# ET6801 register map
Vendor: ETMCU Inc.; File version: v0.0.1
CPU: CM7 r2p1, little endian, MPU, FPU, I-cache, D-cache, ITCM, DTCM, 4 interrupt priority bits
Registers are 32-bit, read-write, reset 0x0 unless marked. A register's access mark holds for its fields unless they carry their own. Offsets are from the block's base; [hi:lo] are bit positions.

## UART0 — Provide an overview of the purpose and functionality of the peripheral: UART
Base 0x40500000
Same registers: UART1 0x40501000, UART2 0x40502000, UART3 0x40503000, UART4 0x40504000, UART5 0x40505000, UART6 0x40506000, UART7 0x40507000
0x00 RBR read — Receive Buffer Register.
  [15:0] RBR — This register contains the data byte received on the serial input port (sin) in UART mode or the serial infrared input(sir_in) in infrared mode. The data in this register is valid only if the Data Ready (DR) bit in the Line status Register(LSR) is set.
0x00 THR write — Transmit Holding Register.This register can be accessed only when the DLAB bit (LCR) is cleared.
  [15:0] THR — This register contains data to be transmitted on the serial output port (sout) in UART mode or the serial infrared output(sir_out_n) in infrared mode.
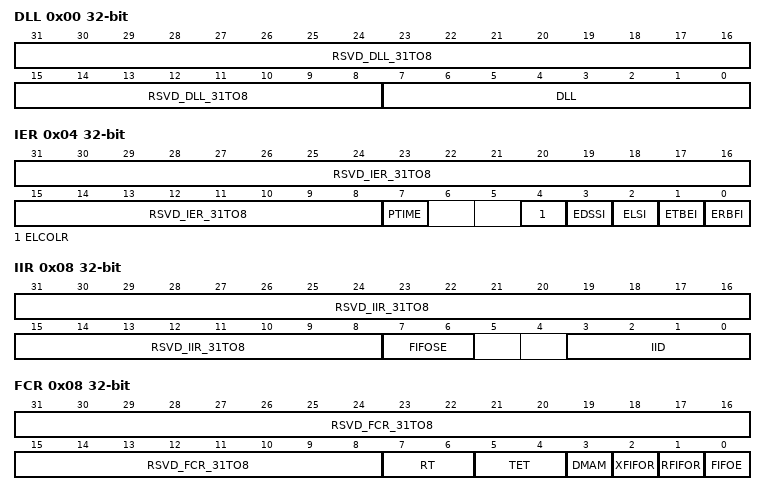
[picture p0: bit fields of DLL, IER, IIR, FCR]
0x00 DLL — Divisor Latch (Low).This register can be accessed only when the DLAB bit (LCR) is set and the UART is not busy.
  [31:8] RSVD_DLL_31TO8 read — DLL 31to8 Reserved bits and read as zero (0)
  [7:0] DLL — This register makes up the lower 8-bits of a 16-bit, read/write, Divisor Latch register that contains the baud rate divisor for the UART.
0x04 IER — Interrupt Enable Register.This register can be accessed only when the DLAB bit (LCR) is cleared.
  [31:8] RSVD_IER_31TO8 read — IER 31to8 Reserved bits and read as zero (0).
  [7] PTIME — This is used to enable/disable the generation of THRE Interrupt
  [4] ELCOLR — Interrupt Enable Register: ELCOLR, this bit controls the method for clearing the status in the LSR register. This is applicable only for Overrun Error, Parity Error, Framing Error, and Break Interrupt status bits
  [3] EDSSI — This is used to enable/disable the generation of Receiver Line Status Interrupt.This is the highest priority interrupt.
  [2] ELSI — This is used to enable/disable the generation of Transmitter Holding Register Empty Interrupt. This is the third highest priority interrupt.
  [1] ETBEI — This is used to enable/disable the generation of Received Data Available Interrupt and the Character Timeout Interrupt (if in FIFO mode and FIFO's enabled). These are the second highest priority interrupts.
  [0] ERBFI — This is used to enable/disable the generation of Received Data Available Interrupt and the Character Timeout Interrupt (if in FIFO mode and FIFO's enabled). These are the second highest priority interrupts
0x04 DLH (alternate view of IER) — Divisor Latch High (DLH) Register.This register can be accessed only when the DLAB bit(LCR) is set and the UART is not busy.
  [7:0] DLH — Upper 8-bits of a 16-bit, read/write, Divisor Latch register that contains the baud rate divisor for the UART.
0x08 IIR read — Interrupt Identification Register
  [31:8] RSVD_IIR_31TO8 — IIR 31to8 Reserved bits and read as 0.
  [7:6] FIFOSE — This is used to indicate whether the FIFOs are enabled or disabled.
  [3:0] IID — This indicates the highest priority pending interrupt which can be one of the following types specified in Values.
0x08 FCR (alternate view of IIR) — FIFO Control Register
  [31:8] RSVD_FCR_31TO8 read — FCR 31to8 Reserved bits and read as 0
  [7:6] RT write — This is used to select the trigger level in the receiver FIFO at which the Received Data Available Interrupt will be generated. In auto flow control mode, it is used to determine when the rts_n signal will be de-asserted only when RTC_FCT is disabled.
  [5:4] TET write — This is used to select the empty threshold level at which the THRE Interrupts will be generated when the mode is active.
  [3] DMAM write — This is used to select DMA mode
  [2] XFIFOR write — This resets the control portion of the transmit FIFO and treats the FIFO as empty. This will also de-assert the DMA TX request and single signals when additional DMA handshaking signals are selected.
  [1] RFIFOR write — This resets the controlportion of the receive FIFO and treats the FIFO as empty. This will also de-assert the DMA RX request and single signals when additional DMA handshaking signals are selected.
  [0] FIFOE write — This enables/disables the transmit(XMIT) and receive (RCVR) FIFOs.
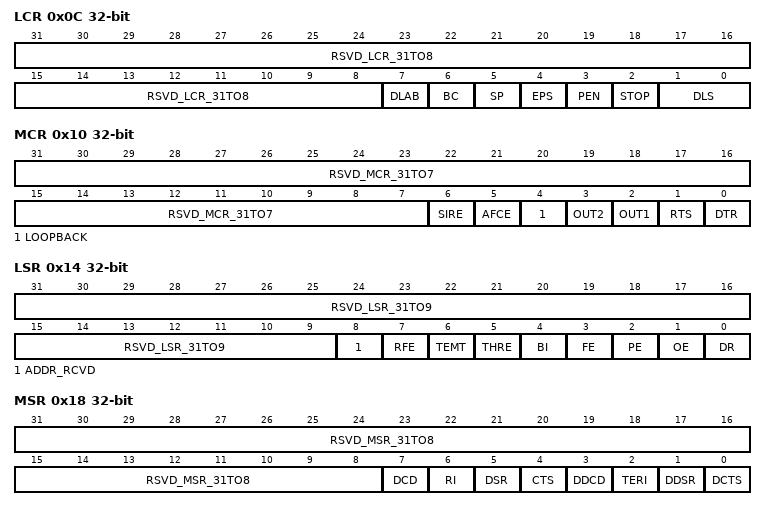
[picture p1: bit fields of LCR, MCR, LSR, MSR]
0x0C LCR — Line Control Register
  [31:8] RSVD_LCR_31TO8 read — LCR 31to8 Reserved bits and read as 0.
  [7] DLAB — Divisor Latch Access Bit.This bit is used to enable reading and writing of the Divisor Latch register (DLL and DLH/LPDLL and LPDLH) to set the baud rate of the UART.
  [6] BC — This is used to cause a break condition to be transmitted to the receiving device.
  [5] SP — writeable only when UART is not busy (USR[0] is 0);
  [4] EPS — writeable only when UART is not busy (USR[0] is zero), otherwise always writable and always readable.
  [3] PEN — writeable only when UART is not busy (USR[0] is zero), otherwise always writable and always readable.
  [2] STOP — writeable only when UART is not busy (USR[0] is zero), otherwise always writable and always readable.
  [1:0] DLS — writeable only when UART is not busy (USR[0] is zero), otherwise always writable and always readable.
0x10 MCR
  [31:7] RSVD_MCR_31TO7 read — MCR 31to7 Reserved bits read as 0.
  [6] SIRE — This is used to enable/ disable the IrDA SIR Mode features as described in section 'IrDA 1.0 SIR Protocol' in the databook.
  [5] AFCE — When FIFOs are enabled and the Auto Flow Control Enable (AFCE) bit is set, Auto Flow Control features are enabled as described in section 'Auto Flow Control' in data book.
  [4] LOOPBACK — LoopBack Bit
  [3] OUT2 — This is used to directly control the user-designated Output2 (out2_n) output.
  [2] OUT1 — This is used to directly control the Request to Send (rts_n) output. The Request To Send (rts_n) output is used to inform the modem or data set that the UART is ready to exchange data.
  [1] RTS — This is used to directly control the Request to Send (rts_n) output. The Request To Send (rts_n) output is used to inform the modem or data set that the UART is ready to exchange data.
  [0] DTR — This is used to directly control the Data Terminal Ready (dtr_n) output. The value written to this location is inverted and driven out on dtr_n.
0x14 LSR read — Line Status Register
  [31:9] RSVD_LSR_31TO9 — LSR 31to9 Reserved bits read as zero.
  [8] ADDR_RCVD — This bit is used to indicate the 9th bit of the receive data is set to 1. This bit can also be used to indicate whether the incoming character is address or data.
  [7] RFE — This is used to indicate if there is at least one parity error, framing error, or break indication in the FIFO.
  [6] TEMT — This bit is set whenever the Transmitter Shift Register and the FIFO are both empty. If in the non-FIFO mode or FIFO's are disabled, this bit is set whenever the Transmitter Holding Register and the Transmitter Shift Register are both empty.
  [5] THRE — This bit indicates that the THR or TX FIFO is empty.
  [4] BI — This is used to indicate the detection of a break sequence on the serial input data.
  [3] FE — This is used to indicate the occurrence of a framing error in the receiver. A framing error occurs when the receiver does not detect a valid STOP bit in the received data.
  [2] PE — This is used to indicate the occurrence of a parity error in the receiver if the Parity Enable (PEN) bit (LCR[3]) is set. In the FIFO mode, since the parity error is associated with a character received, it is revealed when the character with the parity error arrives at the top of the FIFO.
  [1] OE — This is used to indicate the occurrence of an overrun error. This occurs if a new data character was received before the previous data was read.
  [0] DR — This is used to indicate that the receiver contains at least one character in the RBR or the receiver FIFO. This bit is cleared when the RBR is read in the non-FIFO mode, or when the receiver FIFO is empty, in the FIFO mode.
0x18 MSR read — Modem Status Register
  [31:8] RSVD_MSR_31TO8 — MSR 31to8 Reserved bits read as 0.
  [7] DCD — This is used to indicate the current state of the modem control line dcd_n. That is this bit is the complement dcd_n. When the Data Carrier Detect input (dcd_n) is asserted it is an indication that the carrier has been detected by the modem or data set.
  [6] RI — This is used to indicate the current state of the modem control line ri_n. That is this bit is the complement ri_n. When the Ring Indicator input (ri_n) is asserted it is an indication that a telephone ringing signal has been received by the modem or data set.
  [5] DSR — This is used to indicate the current state of the modem control line dsr_n. That is this bit is the complement dsr_n. When the Data Set Ready input (dsr_n) is asserted it is an indication that the modem or data set is ready to establish communications with the DW_apb_uart.
  [4] CTS — This is used to indicate the current state of the modem control line cts_n.
  [3] DDCD — This is used to indicate that the modem control line dcd_n has changed since the last time the MSR was read.
  [2] TERI — This is used to indicate that a change on the input ri_n (from an active low, to an inactive high state) has occurred since the last time the MSR was read.
  [1] DDSR — This is used to indicate that the modem control line dsr_n has changed since the last time the MSR was read.
  [0] DCTS — This is used to indicate that the modem control line cts_n has changed since the last time the MSR was read.
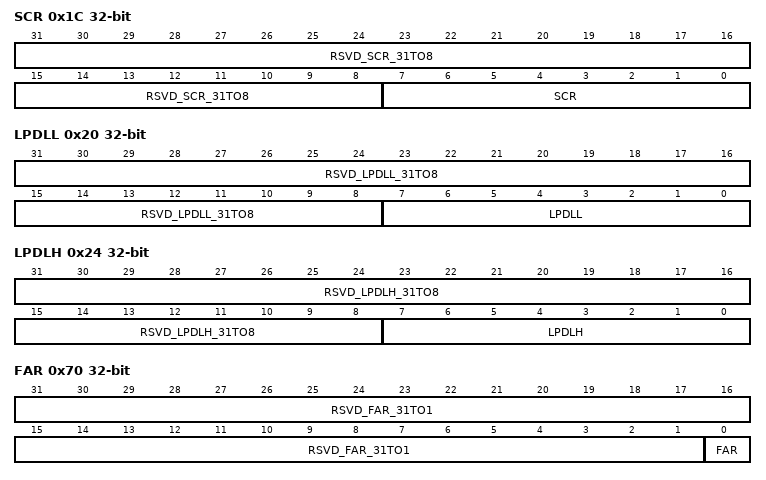
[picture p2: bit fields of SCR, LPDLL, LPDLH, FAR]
0x1C SCR — Scratchpad Register
  [31:8] RSVD_SCR_31TO8 read — SCR 31to8 Reserved bits read as 0.
  [7:0] SCR — This register is for programmers to use as a temporary storage space. It has no defined purpose in the Uart.
0x20 LPDLL — Low Power Divisor Latch Low
  [31:8] RSVD_LPDLL_31TO8 read — LPDLL 31to8 Reserved bits read as 0.
  [7:0] LPDLL — This register makes up the lower 8-bits of a 16-bit, read/write, Low Power Divisor Latch register that contains the baud rate divisor for the UART which must give a baud rate of 115.2K. This is required for SIR Low Power (minimum pulse width) detection at the receiver.
0x24 LPDLH — Low Power Divisor Latch High
  [31:8] RSVD_LPDLH_31TO8 read — LPDLH 31to8 Reserved and read as 0.
  [7:0] LPDLH — This register makes up the upper 8-bits of a 16-bit, read/write, Low Power Divisor Latch register that contains the baud rate divisor for the UART which must give a baud rate of 115.2K.
0x30 SRBR read — Shadow Receive Buffer Register
  [15:0] SRBRN — Shadow Receive Buffer Register n. This is a shadow register for the RBR and has been allocated sixteen 32-bit locations so as to accommodate burst accesses from the master. This register contains the data byte received on the serial input port (sin) in UART mode or the serial infrared input (sir_in) in infrared mode. The data in this register is valid only if the Data Ready (DR) bit in the Line status Register (LSR) is set.
0x30 STHR write — Shadow Transmit Holding Register.
  [15:0] STHRN — Shadow Transmit Holding Register n. This is a shadow register for the THR and has been allocated sixteen 32-bit locations so as to accommodate burst accesses from the master. This register contains data to be transmitted on the serial output port (sout) in UART mode or the serial infrared output (sir_out_n) in infrared mode. Data should only be written to the THR when the THR Empty (THRE) bit (LSR[5])is set.
0x70 FAR — FIFO Access Register.
  [31:1] RSVD_FAR_31TO1 read — FAR 31to1 Reserved bits read as 0.
  [0] FAR — Writes will have no effect when FIFO_ACCESS == No, always readable. This register is use to enable a FIFO access mode for testing, so that the receive FIFO can be written by the master and the transmit FIFO can be read by the master when FIFO's are implemented and enabled. When FIFOs are not implemented or not enabled it allows the RBR to be written by the master and the THR to be read by the master.
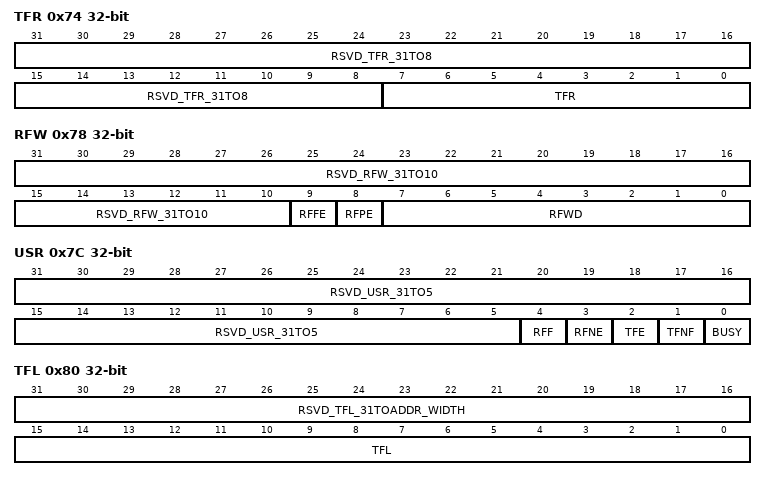
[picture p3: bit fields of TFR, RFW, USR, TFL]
0x74 TFR
  [31:8] RSVD_TFR_31TO8 read — TFR 31to8 Reserved bits read as 0.
  [7:0] TFR read — These bits are only valid when FIFO access mode is enabled(FAR[0] is set to one). When FIFO's are implemented and enabled, reading this register gives the data at the top of the transmit FIFO. Each consecutive read pops the transmit FIFO and gives the next data value that is currently at the top of the FIFO. When FIFO's are not implemented or not enabled, reading this register gives the data in the THR.
0x78 RFW — Receive FIFO Write
  [31:10] RSVD_RFW_31TO10 read — RFW 31to10 Reserved bits read as 0.
  [9] RFFE write — These bits are only valid when FIFO access mode is enabled(FAR[0] is set to one). When FIFO's are implemented and enabled, this bit is used to write framing error detection information to the receive FIFO. When FIFO's are not implemented or not enabled, this bit is used to write framing error detection information to the RBR.
  [8] RFPE write — These bits are only valid when FIFO access mode is enabled(FAR[0] is set to one). When FIFO's are implemented and enabled, this bit is used to write parity error detection information to the receive FIFO. When FIFO's are not implemented or not enabled, this bit is used to write parity error detection information to the RBR.
  [7:0] RFWD write — These bits are only valid when FIFO access mode is enabled (FAR[0] is set to one). When FIFO's are implemented and enabled, the data that is written to the RFWD is pushed into the receive FIFO. Each consecutive write pushes the new data to the next write location in the receive FIFO. When FIFO's are not implemented or not enabled, the data that is written to the RFWD is pushed into the RBR.
0x7C USR — UART Status register
  [31:5] RSVD_USR_31TO5 read — USR 31to5 Reserved bits read as 0.
  [4] RFF read — This bit is only valid when FIFO_STAT == YES. This is used to indicate that the receive FIFO is completely full. That is: This bit is cleared when the RX FIFO is no longer full.
  [3] RFNE read — This bit is only valid when FIFO_STAT == YES. This is used to indicate that the receive FIFO contains one or more entries. This bit is cleared when the RX FIFO is empty.
  [2] TFE read — This bit is only valid when FIFO_STAT == YES. This is used to indicate that the transmit FIFO is completely empty. This bit is cleared when the TX FIFO is no longer empty.
  [1] TFNF read — This bit is only valid when FIFO_STAT == YES. This is used to indicate that the transmit FIFO is not full. This bit is cleared when the TX FIFO is full.
  [0] BUSY read — This indicates that a serial transfer is in progress, when cleared indicates that the DW_apb_uart is idle or inactive.
0x80 TFL — Transmit FIFO Level.
  [31:16] RSVD_TFL_31TOADDR_WIDTH read — TFL 31 to ADDR_WIDTH Reserved bits read as 0.
  [15:0] TFL read — This indicates the number of data entries in the transmit FIFO.
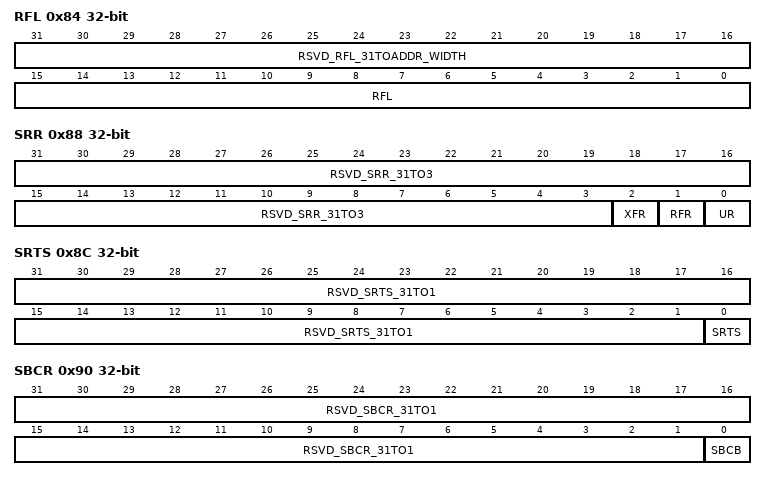
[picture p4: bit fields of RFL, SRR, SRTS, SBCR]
0x84 RFL — This indicates the number of data entries in the transmit FIFO.
  [31:16] RSVD_RFL_31TOADDR_WIDTH read — RFL 31 to ADDR_WIDTH Reserved bits read as 0.
  [15:0] RFL read — This indicates the number of data entries in the receive FIFO.
0x88 SRR — Software Reset Register.
  [31:3] RSVD_SRR_31TO3 read — SRR 31to3 Reserved bits read as 0.
  [2] XFR write — Thisis a shadow register for the XMIT FIFO Reset bit (FCR[2]). This can be used to remove the burden on software having to store previously written FCR values (which are pretty static) just to reset the transmit FIFO. This resets the control portion of the transmit FIFO and treats the FIFO as empty.
  [1] RFR write — This is a shadow register for the RCVR FIFO Reset bit (FCR[1]). This can be used to remove the burden on software having to store previously written FCR values (which are pretty static) just to reset the reeive FIFO. This resets the control portion of the receive FIFO and treats the FIFO as empty.
  [0] UR write — This asynchronously resets the DW_apb_uart and synchronously removes the reset assertion. For a two clock implementation both pclk and sclk domains will be reset.
0x8C SRTS — Shadow Request to Send.
  [31:1] RSVD_SRTS_31TO1 read — SRTS 31to1 Reserved bits read as 0.
  [0] SRTS — This is a shadow register for the RTS bit (MCR[1]), this can be used to remove the burden of having to performing a read modify write on the MCR.
0x90 SBCR — Shadow Break Control Register.
  [31:1] RSVD_SBCR_31TO1 read — SBCR 31to1 Reserved bits read as 0.
  [0] SBCB — This is a shadow register for the Break bit (LCR[6]), this can be used to remove the burden of having to performing a read modify write on the LCR.
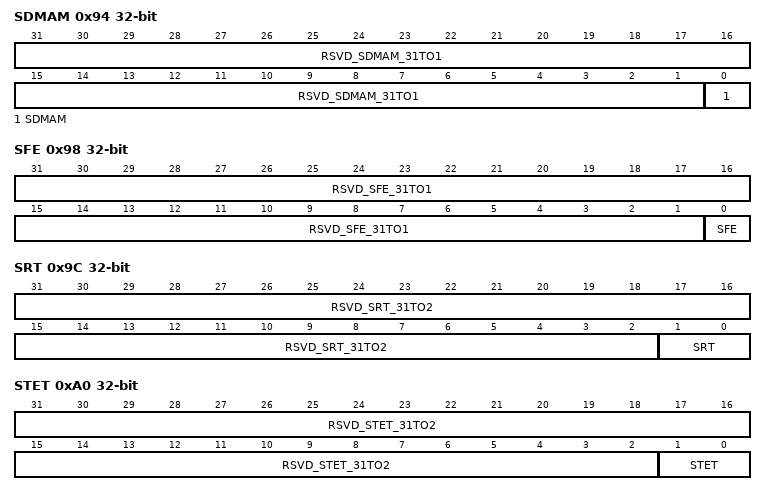
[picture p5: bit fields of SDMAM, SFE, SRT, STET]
0x94 SDMAM — Shadow DMA Mode Register.
  [31:1] RSVD_SDMAM_31TO1 read — SDMAM 31to1 Reserved bits read as 0.
  [0] SDMAM — This is a shadow register for the DMA mode bit (FCR[3]). This can be used to remove the burden of having to store the previously written value to the FCR in memory and having to mask this value so that only the DMA Mode bit gets updated. This determines the DMA signalling mode used for the dma_tx_req_n and dma_rx_req_n output signals when additional DMA handshaking signals are not selected (DMA_EXTRA == NO).
0x98 SFE — Shadow FIFO Enable Register.
  [31:1] RSVD_SFE_31TO1 read — SFE 31to1 Reserved bits read as 0.
  [0] SFE — This is a shadow register for the FIFO enable bit (FCR[0]). This can be used to remove the burden of having to store the previously written value to the FCR in memory and having to mask this value so that only the FIFO enable bit gets updated. This enables/disables the transmit (XMIT) and receive (RCVR) FIFO's. If this bit is set to zero (disabled) after being enabled then both the XMIT and RCVR controller portion of FIFO's will be reset.
0x9C SRT — Shadow RCVR Trigger Register.
  [31:2] RSVD_SRT_31TO2 read — SRT 31to2 Reserved bits read as 0.
  [1:0] SRT — This is a shadow register for the RCVR trigger bits(FCR[7:6]). This can be used to remove the burden of having to store the previously written value to the FCR in memory and having to mask this value so that only the RCVR trigger bit gets updated.
0xA0 STET — Shadow TX Empty Trigger Register.
  [31:2] RSVD_STET_31TO2 read — STET 31to2 Reserved bits read as 0.
  [1:0] STET — This is a shadow register for the TX empty trigger bits (FCR[5:4]). This can be used to remove the burden of having to store the previously written value to the FCR in memory and having to mask this value so that only the TX empty trigger bit gets updated.
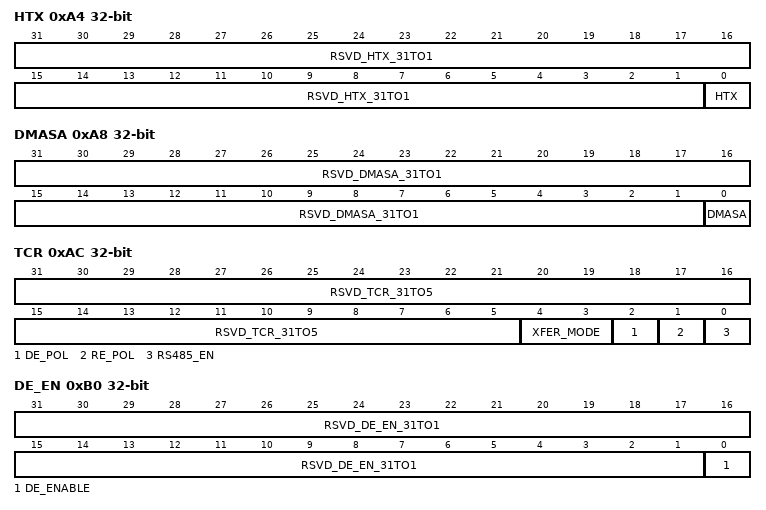
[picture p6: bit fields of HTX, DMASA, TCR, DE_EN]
0xA4 HTX — Halt TX
  [31:1] RSVD_HTX_31TO1 read — HTX 31to1 Reserved bits read as 0.
  [0] HTX * Varies — This register is use to halt transmissions for testing, so that the transmit FIFO can be filled by the master when FIFO's are implemented and enabled.
0xA8 DMASA — DMA Software Acknowledge Register.
  [31:1] RSVD_DMASA_31TO1 read — DMASA 31to1 Reserved bits read as 0.
  [0] DMASA write — This register is use to perform DMA software acknowledge if a transfer needs to be terminated due to an error condition. For example, if the DMA disables the channel, then the uart should clear its request.
0xAC TCR — Transceiver Control Register.
  [31:5] RSVD_TCR_31TO5 read — TCR 31to5 Reserved bits read as 0.
  [4:3] XFER_MODE — Transfer Mode.
  [2] DE_POL — Driver Enable Polarity.
  [1] RE_POL — Receiver Enable Polarity.
  [0] RS485_EN — RS485 Transfer Enable.
0xB0 DE_EN — Driver Output Enable Register.
  [31:1] RSVD_DE_EN_31TO1 read — DE_EN 31to1 Reserved bits read as 0.
  [0] DE_ENABLE — The 'DE Enable' register bit is used to control assertion and de-assertion of 'de' signal.
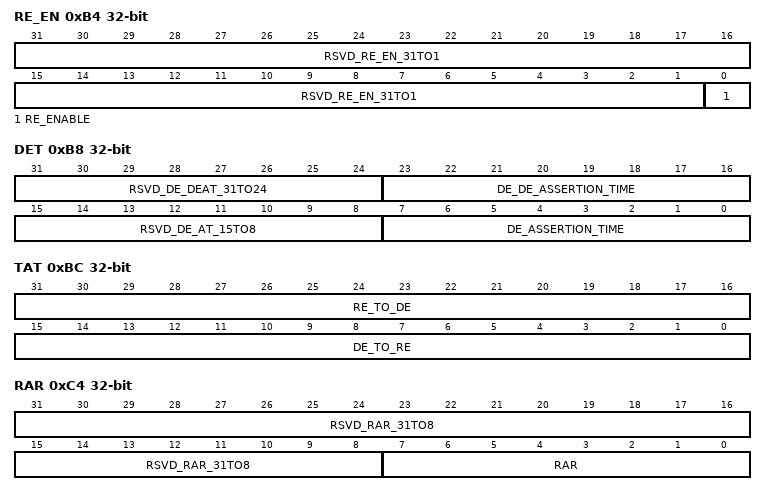
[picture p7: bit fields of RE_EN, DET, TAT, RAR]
0xB4 RE_EN — Receiver Output Enable Register.
  [31:1] RSVD_RE_EN_31TO1 read — RE_EN 31to1 Reserved bits read as 0.
  [0] RE_ENABLE — The 'RE Enable' register bit is used to control assertion and de-assertion of 're' signal.
0xB8 DET — Driver Output Enable Timing Register.
  [31:24] RSVD_DE_DEAT_31TO24 read — DET 31to24 Reserved bits read as 0.
  [23:16] DE_DE_ASSERTION_TIME — Driver Enable de-assertion time.
  [15:8] RSVD_DE_AT_15TO8 read — DET 15to8 Reserved bits read as 0.
  [7:0] DE_ASSERTION_TIME — Driver Enable assertion time.
0xBC TAT — TurnAround Timing Register.
  [31:16] RE_TO_DE — Receiver Enable to Driver Enable TurnAround time.
  [15:0] DE_TO_RE — Driver Enable to Receiver Enable TurnAround time.
0xC0 DLF — Divisor Latch Fraction Register.
  [4:0] DLF — The fractional value is added to integer value set by DLH,DLL.
0xC4 RAR — Receive Address Register
  [31:8] RSVD_RAR_31TO8 read — RAR 31to8 Reserved bits read as 0.
  [7:0] RAR — This is an address matching register during receive mode. If the 9-th bit is set in the incoming character then the remaining 8-bits will be checked against this register value. If the match happens then sub-sequent characters with 9-th bit set to 0 will be treated as data byte until the next address byte is received.
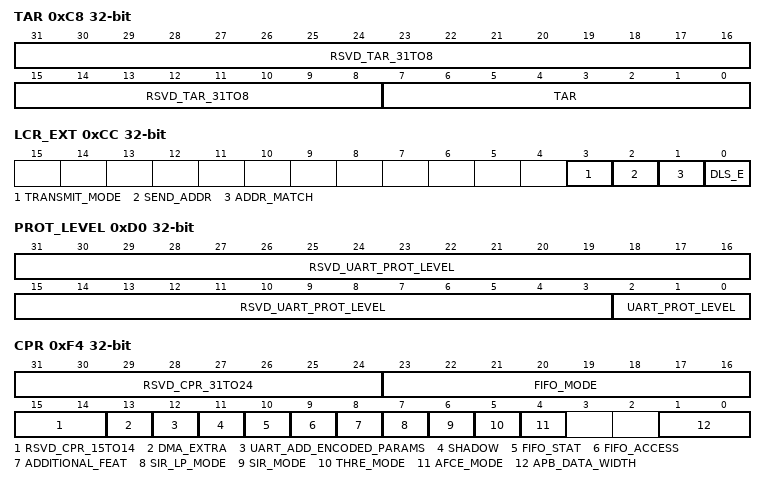
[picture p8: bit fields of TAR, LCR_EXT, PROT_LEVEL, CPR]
0xC8 TAR — Transmit Address Register.
  [31:8] RSVD_TAR_31TO8 read — TAR 31to8 Reserved bits read as 0.
  [7:0] TAR — This is an address matching register during transmit mode. If DLS_E (LCR_EXT[0]) bit is enabled, then uart will send the 9-bit character with 9-th bit set to 1 and remaining 8-bit address will be sent from this register provided 'SEND_ADDR' (LCR_EXT[2]) bit is set to 1.
0xCC LCR_EXT — Line Extended Control Register.
  [3] TRANSMIT_MODE — Transmit mode control bit. This bit is used to control the type of transmit mode during 9-bit data transfers.
  [2] SEND_ADDR — Send address control bit. This bit is used as a control knob for the user to determine when to send the address during transmit mode.
  [1] ADDR_MATCH — Address Match Mode.This bit is used to enable the address match feature during receive.
  [0] DLS_E — Extension for DLS. This bit is used to enable 9-bit data for transmit and receive transfers.
0xD0 PROT_LEVEL — UART Protection level
  [31:3] RSVD_UART_PROT_LEVEL read — UART_PROT_LEVEL[31:29] Reserved field-read-only.
  [2:0] UART_PROT_LEVEL — Protection level register.
0xD4 REG_TIMEOUT_RST — Register timeout counter reset value
  [31:0] RSVD_REG_TIMEOUT_RST read — Reserved bits - Read Only
0xF4 CPR — Component Parameter Register
  [31:24] RSVD_CPR_31TO24 read — CPR 31to24 Reserved bits read as 0.
  [23:16] FIFO_MODE read — Encoding of FIFO_MODE configuration parameter value.
  [15:14] RSVD_CPR_15TO14 read — CPR 15to14 Reserved bits read as 0.
  [13] DMA_EXTRA read — Encoding of DMA_EXTRA configuration parameter value.
  [12] UART_ADD_ENCODED_PARAMS read — Encoding of UART_ADD_ENCODED_PARAMS configuration parameter value.
  [11] SHADOW read — Encoding of SHADOW configuration parameter value.
  [10] FIFO_STAT read — Encoding of FIFO_STAT configuration parameter value.
  [9] FIFO_ACCESS read — Encoding of FIFO_ACCESS configuration parameter value.
  [8] ADDITIONAL_FEAT read — Encoding of ADDITIONAL_FEATURES configuration parameter value.
  [7] SIR_LP_MODE read — Nestor_write
  [6] SIR_MODE read — Encoding of SIR_MODE configuration parameter value.
  [5] THRE_MODE read — Encoding of THRE_MODE configuration parameter value.
  [4] AFCE_MODE read — Encoding of AFCE_MODE configuration parameter value.
  [1:0] APB_DATA_WIDTH read — Encoding of APB_DATA_WIDTH configuration parameter value.
0xF8 UCV — UART Component Version
  [31:0] UART_COMPONENT_VERSION read — ASCII value for each number in the version, followed by ETMCU.
0xFC CTR — Component Type Register
  [31:0] PERIPHERAL_ID read — This register contains the peripherals identification code.
